# A31G324 register map
Vendor: ABOV Semiconductor Co., Ltd.; Series: A31G324; File version: 1.0
ARM 32-bit Cortex-M0+ Microcontroller based device, CPU clock up to 48MHz, etc.
CPU: CM0PLUS r0p1, little endian, no MPU, no FPU, VTOR, 2 interrupt priority bits
Registers are 32-bit, read-write, reset 0x0 unless marked. A register's access mark holds for its fields unless they carry their own. Offsets are from the block's base; lines under a group give offsets from that group; [hi:lo] are bit positions; {n}, {i} and the like mark numbered series; 'fields as' and 'values as' point back to an identical list; <NAME> marks a mode.

## Memory map
0x40000000 SCU size 0x100 — System Control Unit
0x40000100 FMC size 0x40 — FLASH MEMORY CONTROLLER
0x40000300 CRC size 0x20 — CYCLIC REDUNDANCY CHECK AND CHECKSUM
0x40000400 DMAC0 size 0x10 — DIRECT MEMORY ACCESS CONTROLLER
0x40000410 DMAC1 size 0x10
0x40000420 DMAC2 size 0x10
0x40000430 DMAC3 size 0x10
0x40001000 PA size 0x100 — General Port A
0x40001100 PB size 0x100
0x40001200 PC size 0x100
0x40001500 PF size 0x100
0x40001A00 WDT size 0x20 — WATCH-DOG TIMER
0x40001FF0 PCU size 0x10 — Port Control Mode Enable Register
0x40002000 WT size 0x10 — WATCH TIMER
0x40002100 TIMER10 size 0x100 — TIMER COUNTER 10/11/12/13
0x40002200 TIMER11 size 0x100
0x40002300 TIMER12 size 0x100
0x40002400 TIMER30 size 0x40 — TIMER COUNTER 30
0x40002500 TIMER20 size 0x20 — TIMER COUNTER 20/21
0x40002600 TIMER21 size 0x20
0x40002700 TIMER13 size 0x100
0x40002800 TIMER40 size 0x40 — TIMER COUNTER 40
0x40002B00 HSICMU size 0x1C
0x40003000 ADC size 0x80 — 12-BIT A/D CONVERTER
0x40003420 COMP size 0x24 — COMPARATOR
0x40003500 DAC size 0x24 — 12-BIT D/A CONVERTER
0x40003800 USART10 size 0x100 — USART 10 (UART + SPI)
0x40003900 USART11 size 0x100
0x40003A00 USART12 size 0x100
0x40003B00 USART13 size 0x100
0x40004800 I2C0 size 0x100
0x40004900 I2C1 size 0x100
0x40004C00 SPI20 size 0x20 — Serial Peripheral Interface
0x40004D00 SPI21 size 0x20
0x40005100 SCULV size 0xC — LOW VOLTAGE INDICATOR(LVI) AND LOW VOLTAGE RESET(LVR)
0x40006100 RTC size 0x50 — Real-time clock
0x40006200 EBI size 0x20 — Static memory controller
0x40006300 TEMP size 0x10 — Temp Sensor
0x4000F000 SCUCC size 0xC — CHIP CONFIGURATION
0x50000000 USB size 0xE04

## Interrupts
0 LVI (SCULV)
1 SYSCLKFAIL (SCUCC)
2 WDT
3 GPIOAB (PA)
4 GPIOCF (PA)
7 TIMER10
8 TIMER11
9 TIMER12
10 I2C0
11 USART10
12 WT
13 TIMER30
14 I2C1
15 TIMER20
16 TIMER21
17 USART11
18 ADC
19 SPI20
20 SPI21
21 TIMER13
22 TIMER40
23 RTC
26 USART12
27 USART13
28 TEMPERATURE (TEMP)
29 COMP
30 USB
31 CRC

## SCUCC — CHIP CONFIGURATION
Base 0x4000F000
0x00 VENDORID ro reset 0x41424F56 — Vendor Identification Register
  [31:0] VENDID — Vendor Identification bits
0x04 CHIPID ro reset 0x4D31A003 — Chip Identification Register
  [31:0] CHIPID — Chip Identification bits. 0x4D31F000: 32k bytes flash memory for program 0x4D31F001: 16k bytes flash memory for program
0x08 REVNR ro — Revision Number Register
  [7:0] REVNO — Chip Revision Number. These bits are fixed by manufacturer.

## SCULV — LOW VOLTAGE INDICATOR(LVI) AND LOW VOLTAGE RESET(LVR)
Base 0x40005100
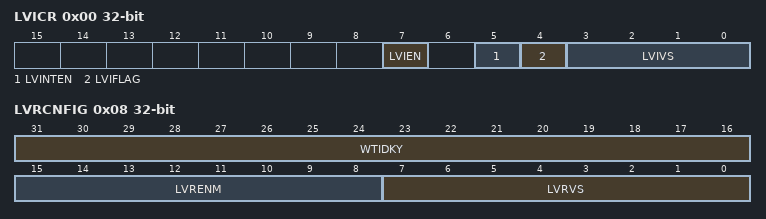
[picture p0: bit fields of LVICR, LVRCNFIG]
0x00 LVICR — Low Voltage Indicator Control Register
  [7] LVIEN — LVI Enable bit
  [5] LVINTEN — LVI Interrupt Enable bit
  [4] LVIFLAG — LVI Interrupt Flag bit
  [3:0] LVIVS — LVI Voltage Selection bits
0x04 LVRCR — Low Voltage Reset Control Register
  [7:0] LVREN — LVR Enable bits
0x08 LVRCNFIG — Configuration for Low Voltage Reset
  [31:16] WTIDKY wo — Write Identification Key On writes, write 0x72A5 to these bits, otherwise the write is ignored.
  [15:8] LVRENM — LVR Reset Operation Control Master Configuration
  [7:0] LVRVS — LVR Voltage Selection bits

## Licence text in the file
ARM Limited (ARM) is supplying this software for use with Cortex-M processor based microcontroller, but can be equally used for other suitable processor architectures. This file can be freely distributed. Modifications to this file shall be clearly marked. . THIS SOFTWARE IS PROVIDED "AS IS". NO WARRANTIES, WHETHER EXPRESS, IMPLIED. OR STATUTORY, INCLUDING, BUT NOT LIMITED TO, IMPLIED WARRANTIES OF. MERCHANTABILITY AND FITNESS FOR A PARTICULAR PURPOSE APPLY TO THIS SOFTWARE. ARM SHALL NOT, IN ANY CIRCUMSTANCES, BE LIABLE FOR SPECIAL, INCIDENTAL, OR. CONSEQUENTIAL DAMAGES, FOR ANY REASON WHATSOEVER.

## Notices in the file
Copyright (C) 2012-2014 ARM Limited. All rights reserved.
Purpose: System Viewer Description (SVD) Example (Schema Version 1.1)
This is a description of a none-existent and incomplete device
for demonstration purposes only.
Redistribution and use in source and binary forms, with or without
modification, are permitted provided that the following conditions are met:
- Redistributions of source code must retain the above copyright
notice, this list of conditions and the following disclaimer.
- Redistributions in binary form must reproduce the above copyright
notice, this list of conditions and the following disclaimer in the
documentation and/or other materials provided with the distribution.
- Neither the name of ARM nor the names of its contributors may be used
to endorse or promote products derived from this software without
specific prior written permission.
THIS SOFTWARE IS PROVIDED BY THE COPYRIGHT HOLDERS AND CONTRIBUTORS "AS IS"
AND ANY EXPRESS OR IMPLIED WARRANTIES, INCLUDING, BUT NOT LIMITED TO, THE
ARE DISCLAIMED. IN NO EVENT SHALL COPYRIGHT HOLDERS AND CONTRIBUTORS BE
LIABLE FOR ANY DIRECT, INDIRECT, INCIDENTAL, SPECIAL, EXEMPLARY, OR
CONSEQUENTIAL DAMAGES (INCLUDING, BUT NOT LIMITED TO, PROCUREMENT OF
SUBSTITUTE GOODS OR SERVICES; LOSS OF USE, DATA, OR PROFITS; OR BUSINESS
INTERRUPTION) HOWEVER CAUSED AND ON ANY THEORY OF LIABILITY, WHETHER IN
CONTRACT, STRICT LIABILITY, OR TORT (INCLUDING NEGLIGENCE OR OTHERWISE)
ARISING IN ANY WAY OUT OF THE USE OF THIS SOFTWARE, EVEN IF ADVISED OF THE
POSSIBILITY OF SUCH DAMAGE.
